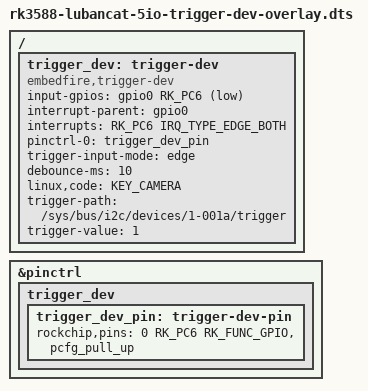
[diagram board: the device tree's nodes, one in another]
/dts-v1/;
/plugin/;

#include <dt-bindings/gpio/gpio.h>
#include <dt-bindings/pinctrl/rockchip.h>
#include <dt-bindings/interrupt-controller/irq.h>
#include <dt-bindings/input/linux-event-codes.h>

/ {
	fragment@0 {
		target = <&pinctrl>;

		__overlay__ {
			trigger_dev {
				trigger_dev_pin: trigger-dev-pin {

					/* GPIO0_C6: 平时高电平，下降沿有效 */
					rockchip,pins = <0 RK_PC6 RK_FUNC_GPIO &pcfg_pull_up>;

					/*
					 * 注意：GPIO0_D3(RK_PD3) 在 LubanCat-5IO 默认 DTS 中
					 * 已被 Type-C 控制器 fusb302 用作中断脚：
					 *   usbc0: fusb302@22 { interrupts = <RK_PD3 ...>; }
					 * 所以不要把 RK_PD3 再拿来做按键输入，否则会冲突、无响应。
					 */

				};
			};
		};
	};

	fragment@1 {
		target-path = "/";

		__overlay__ {
			trigger_dev: trigger-dev {
				compatible = "embedfire,trigger-dev";
				status = "okay";

				/* GPIO0_C6: 默认外部脉冲模式，平时高电平，下降沿有效 */
				input-gpios = <&gpio0 RK_PC6 GPIO_ACTIVE_LOW>;
				interrupt-parent = <&gpio0>;
				/*
				 * DTS 先保持双沿描述，驱动会在 probe 时按 input_mode
				 * 重新切到实际所需的单活动沿/双沿。
				 */
				interrupts = <RK_PC6 IRQ_TYPE_EDGE_BOTH>;

				pinctrl-names = "default";
				pinctrl-0 = <&trigger_dev_pin>;

				/* 输入模式：默认 edge，适合干净外部脉冲 */
				trigger-input-mode = "edge";
				/* 当前默认 edge 模式下该值被忽略；切到 button 时仍可复用 */
				debounce-ms = <10>;

				/* 输入事件码，KEY_CAMERA 用于相机快门 */
				linux,code = <KEY_CAMERA>;

				/*
				 * 通过 IMX296 的 sysfs 触发：
				 * 外部输入(GPIO0_C6) -> trigger-dev -> imx296 trigger
				 * -> GPIO1_D6(PWM14_M2) 输出一次低电平脉冲。
				 */
				trigger-path = "/sys/bus/i2c/devices/1-001a/trigger";
				/* 写入 sysfs 的值，默认 "1" 表示触发一次拍照 */
				trigger-value = "1";
			};
		};
	};
};


